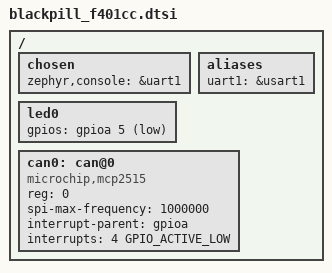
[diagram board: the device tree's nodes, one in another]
/ {
    chosen {
        zephyr,console = &uart1;
    };

    aliases {
        uart1 = &usart1;
    };

    led0: led0 {
        gpios = <&gpioa 5 GPIO_ACTIVE_LOW>;
    };

    can0: can@0 {
        compatible = "microchip,mcp2515";
        reg = <0>;
        spi-max-frequency = <1000000>;
        interrupt-parent = <&gpioa>;
        interrupts = <4 GPIO_ACTIVE_LOW>;
        status = "okay";
    };
};
